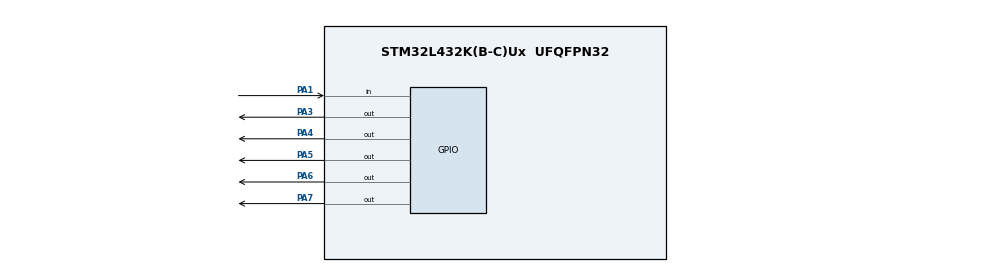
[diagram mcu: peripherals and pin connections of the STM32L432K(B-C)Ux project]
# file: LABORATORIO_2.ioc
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Mcu.Family=STM32L4
Mcu.Name=STM32L432K(B-C)Ux
Mcu.Package=UFQFPN32
NVIC.PriorityGroup=NVIC_PRIORITYGROUP_4
PA1.GPIO_PuPd=GPIO_PULLDOWN
PA1.Signal=GPIO_Input
PA3.Signal=GPIO_Output
PA4.Signal=GPIO_Output
PA5.Signal=GPIO_Output
PA6.Signal=GPIO_Output
PA7.Signal=GPIO_Output
ProjectManager.HeapSize=0x200
ProjectManager.StackSize=0x400
ProjectManager.TargetToolchain=STM32CubeIDE
RCC.HSE_VALUE=8000000
RCC.HSI48_VALUE=48000000
RCC.HSI_VALUE=16000000
RCC.LSE_VALUE=32768
RCC.MSI_VALUE=4000000
RCC.VCOOutputFreq_Value=32000000
board=custom

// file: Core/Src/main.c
/* USER CODE BEGIN Header */
/**
  ******************************************************************************
  * @file           : main.c
  * @brief          : Main program body
  ******************************************************************************
  * @attention
  *
  * Copyright (c) 2022 STMicroelectronics.
  * All rights reserved.
  *
  * This software is licensed under terms that can be found in the LICENSE file
  * in the root directory of this software component.
  * If no LICENSE file comes with this software, it is provided AS-IS.
  *
  ******************************************************************************
  */
/* USER CODE END Header */
#include "main.h"

void SystemClock_Config(void);
static void MX_GPIO_Init(void);

int main(void)
{

  /* MCU Configuration--------------------------------------------------------*/

  /* Reset of all peripherals, Initializes the Flash interface and the Systick. */
  HAL_Init();

  /* Configure the system clock */
  SystemClock_Config();

  /* Initialize all configured peripherals */
  MX_GPIO_Init();

  /* Infinite loop */
  /* USER CODE BEGIN WHILE */
  while (1){
		int c=0;
		while(c<7){
		  HAL_GPIO_WritePin(GPIOA, GPIO_PIN_3, 1);
		  HAL_Delay(1000/(c));
		  HAL_GPIO_WritePin(GPIOA, GPIO_PIN_3, 0);
		  HAL_GPIO_WritePin(GPIOA, GPIO_PIN_4, 1);
		  HAL_Delay(1000/(c));
		  HAL_GPIO_WritePin(GPIOA, GPIO_PIN_4, 0);

		  HAL_GPIO_WritePin(GPIOA, GPIO_PIN_5, 1);
		  if(HAL_GPIO_ReadPin(GPIOA, GPIO_PIN_1)==1){
		  	  c=c+1;
		  	  	  HAL_GPIO_WritePin(GPIOA, GPIO_PIN_3, 1);
		  	 	  HAL_GPIO_WritePin(GPIOA, GPIO_PIN_4, 1);
		  	  	  HAL_GPIO_WritePin(GPIOA, GPIO_PIN_5, 1);
		  	  	  HAL_GPIO_WritePin(GPIOA, GPIO_PIN_6, 1);
		  	  	  HAL_GPIO_WritePin(GPIOA, GPIO_PIN_7, 1);
		  	  	  HAL_Delay(500);
		  	  	  HAL_GPIO_WritePin(GPIOA, GPIO_PIN_3, 0);
		  	 	  HAL_GPIO_WritePin(GPIOA, GPIO_PIN_4, 0);
		  	  	  HAL_GPIO_WritePin(GPIOA, GPIO_PIN_5, 0);
		  	  	  HAL_GPIO_WritePin(GPIOA, GPIO_PIN_6, 0);
		  	  	  HAL_GPIO_WritePin(GPIOA, GPIO_PIN_7, 0);
		  	  }
		  HAL_Delay(1000/(c));
		  HAL_GPIO_WritePin(GPIOA, GPIO_PIN_5, 0);
		  HAL_GPIO_WritePin(GPIOA, GPIO_PIN_6, 1);
		  HAL_Delay(1000/(c));
		  HAL_GPIO_WritePin(GPIOA, GPIO_PIN_6, 0);
		  HAL_GPIO_WritePin(GPIOA, GPIO_PIN_7, 1);
		  HAL_Delay(1000/(c));
		  HAL_GPIO_WritePin(GPIOA, GPIO_PIN_7, 0);
		  }

	  	  HAL_GPIO_WritePin(GPIOA, GPIO_PIN_3, 0);
	 	  HAL_GPIO_WritePin(GPIOA, GPIO_PIN_4, 0);
	  	  HAL_GPIO_WritePin(GPIOA, GPIO_PIN_5, 0);
	  	  HAL_GPIO_WritePin(GPIOA, GPIO_PIN_6, 0);
	  	  HAL_GPIO_WritePin(GPIOA, GPIO_PIN_7, 0);
  }
}

void SystemClock_Config(void)
{
  RCC_OscInitTypeDef RCC_OscInitStruct = {0};
  RCC_ClkInitTypeDef RCC_ClkInitStruct = {0};

  /** Configure the main internal regulator output voltage
  */
  if (HAL_PWREx_ControlVoltageScaling(PWR_REGULATOR_VOLTAGE_SCALE1) != HAL_OK)
  {
    Error_Handler();
  }

  /** Initializes the RCC Oscillators according to the specified parameters
  * in the RCC_OscInitTypeDef structure.
  */
  RCC_OscInitStruct.OscillatorType = RCC_OSCILLATORTYPE_MSI;
  RCC_OscInitStruct.MSIState = RCC_MSI_ON;
  RCC_OscInitStruct.MSICalibrationValue = 0;
  RCC_OscInitStruct.MSIClockRange = RCC_MSIRANGE_6;
  RCC_OscInitStruct.PLL.PLLState = RCC_PLL_NONE;
  if (HAL_RCC_OscConfig(&RCC_OscInitStruct) != HAL_OK)
  {
    Error_Handler();
  }

  /** Initializes the CPU, AHB and APB buses clocks
  */
  RCC_ClkInitStruct.ClockType = RCC_CLOCKTYPE_HCLK|RCC_CLOCKTYPE_SYSCLK
                              |RCC_CLOCKTYPE_PCLK1|RCC_CLOCKTYPE_PCLK2;
  RCC_ClkInitStruct.SYSCLKSource = RCC_SYSCLKSOURCE_MSI;
  RCC_ClkInitStruct.AHBCLKDivider = RCC_SYSCLK_DIV1;
  RCC_ClkInitStruct.APB1CLKDivider = RCC_HCLK_DIV1;
  RCC_ClkInitStruct.APB2CLKDivider = RCC_HCLK_DIV1;

  if (HAL_RCC_ClockConfig(&RCC_ClkInitStruct, FLASH_LATENCY_0) != HAL_OK)
  {
    Error_Handler();
  }
}

static void MX_GPIO_Init(void)
{
  GPIO_InitTypeDef GPIO_InitStruct = {0};

  /* GPIO Ports Clock Enable */
  __HAL_RCC_GPIOA_CLK_ENABLE();

  /*Configure GPIO pin Output Level */
  HAL_GPIO_WritePin(GPIOA, GPIO_PIN_3|GPIO_PIN_4|GPIO_PIN_5|GPIO_PIN_6
                          |GPIO_PIN_7, GPIO_PIN_RESET);

  /*Configure GPIO pin : PA1 */
  GPIO_InitStruct.Pin = GPIO_PIN_1;
  GPIO_InitStruct.Mode = GPIO_MODE_INPUT;
  GPIO_InitStruct.Pull = GPIO_PULLDOWN;
  HAL_GPIO_Init(GPIOA, &GPIO_InitStruct);

  /*Configure GPIO pins : PA3 PA4 PA5 PA6
                           PA7 */
  GPIO_InitStruct.Pin = GPIO_PIN_3|GPIO_PIN_4|GPIO_PIN_5|GPIO_PIN_6
                          |GPIO_PIN_7;
  GPIO_InitStruct.Mode = GPIO_MODE_OUTPUT_PP;
  GPIO_InitStruct.Pull = GPIO_NOPULL;
  GPIO_InitStruct.Speed = GPIO_SPEED_FREQ_LOW;
  HAL_GPIO_Init(GPIOA, &GPIO_InitStruct);

}

void Error_Handler(void)
{
  /* USER CODE BEGIN Error_Handler_Debug */
  /* User can add his own implementation to report the HAL error return state */
  __disable_irq();
  while (1)
  {
	  HAL_GPIO_WritePin(GPIOA, GPIO_PIN_3, 1);
	  HAL_Delay(500);
	  HAL_GPIO_WritePin(GPIOA, GPIO_PIN_3, 0);
	  HAL_Delay(500);

  }
  /* USER CODE END Error_Handler_Debug */
}
